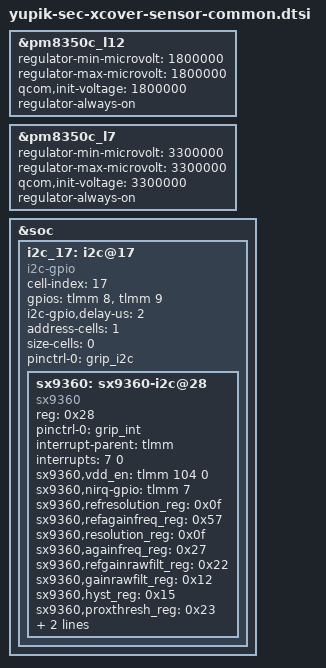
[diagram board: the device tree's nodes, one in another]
/* Copyright (c) 2021, The Linux Foundation. All rights reserved.
 *
 * This program is free software; you can redistribute it and/or modify
 * it under the terms of the GNU General Public License version 2 and
 * only version 2 as published by the Free Software Foundation.
 *
 * This program is distributed in the hope that it will be useful,
 * but WITHOUT ANY WARRANTY; without even the implied warranty of
 * MERCHANTABILITY or FITNESS FOR A PARTICULAR PURPOSE.  See the
 * GNU General Public License for more details.
 */

&pm8350c_l12 {
	regulator-min-microvolt = <1800000>;
	regulator-max-microvolt = <1800000>;
	qcom,init-voltage = <1800000>;
	regulator-always-on;
};
&pm8350c_l7 {
	regulator-min-microvolt = <3300000>;
	regulator-max-microvolt = <3300000>;
	qcom,init-voltage = <3300000>;
	regulator-always-on;
};
&soc {
	i2c_17: i2c@17 { /* SW I2C */
		status = "ok";
		cell-index = <17>;
		compatible = "i2c-gpio";
		gpios = <&tlmm 8 0 /* sda */
			 &tlmm 9 0 /* scl */
		>;
		i2c-gpio,delay-us = <2>;
		address-cells = <1>;
		size-cells = <0>;
		pinctrl-names = "default";
		pinctrl-0 = <&grip_i2c>;

		sx9360: sx9360-i2c@28 {
			compatible = "sx9360";
			reg = <0x28>;
			status = "okay";
			pinctrl-names = "default";
			pinctrl-0 = <&grip_int>;

			interrupt-parent = <&tlmm>;
			interrupts = <7 0>;

			sx9360,vdd_en = <&tlmm 104 0>;
			sx9360,nirq-gpio = <&tlmm 7 0>;

			sx9360,refresolution_reg = <0x0f>; /* same as resolution_reg */
			sx9360,refagainfreq_reg = <0x57>; /* same as againfreq_reg */
			sx9360,resolution_reg = <0x0f>; /* resolution : 1024 */
			sx9360,againfreq_reg = <0x27>; /* freq : 71.43 kHz, again : +/-3.75 pF */
			sx9360,refgainrawfilt_reg = <0x22>; /* same as gainrawfilt_reg */
			sx9360,gainrawfilt_reg = <0x12>; /* rawfilter : 1-1/4, gain : x2 */
			sx9360,hyst_reg = <0x15>; /* hysteresis : +/-6 %, debouncer : 2 samples */
			sx9360,proxthresh_reg = <0x23>; /* threshhold : 612 */
			sx9360,hallic_detect = <1>;
			sx9360,hallic_cert_detect = <1>;
		};
	};
};
